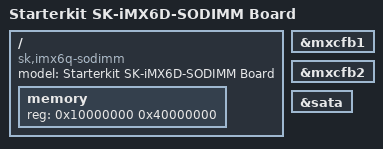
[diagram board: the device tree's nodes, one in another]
/*
 * Copyright 2014 starterkit.ru
 *
 * The code contained herein is licensed under the GNU General Public
 * License V2.
 */

/dts-v1/;

#include "imx6q.dtsi"
#include "imx6qdl-sodimm.dtsi"

/ {
	model = "Starterkit SK-iMX6D-SODIMM Board";
	compatible = "sk,imx6q-sodimm", "fsl,imx6q-sabresd", "fsl,imx6q";

	memory {
		reg = <0x10000000 0x40000000>;
	};
};

&mxcfb1 {
	status = "okay";
};

&mxcfb2 {
	status = "okay";
};

&sata {
	status = "okay";
};
